# GD32F50x register map
File version: 1.0
CPU: CM33 r2p1, little endian, MPU, FPU, 4 interrupt priority bits
Registers are 32-bit, read-write, reset 0x0 unless marked. A register's access mark holds for its fields unless they carry their own. Offsets are from the block's base; [hi:lo] are bit positions; {n}, {i} and the like mark numbered series; 'fields as' and 'values as' point back to an identical list.

## DMAMUX — DMA request multiplexer
Base 0x40020800
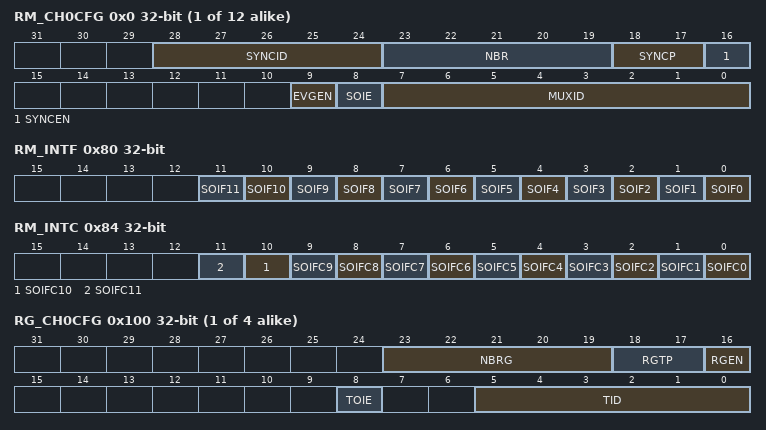
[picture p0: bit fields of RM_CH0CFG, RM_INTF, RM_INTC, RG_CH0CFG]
{0x0+4i} RM_CH{i}CFG (i=0..11) — Request multiplexer channel {i} configuration regist
  [28:24] SYNCID — Synchronization input identification
  [23:19] NBR — Number of DMA requests to forward
  [18:17] SYNCP — Synchronization input polarity
  [16] SYNCEN — Synchronization enable
  [9] EVGEN — Event generation enable
  [8] SOIE — Synchronization overrun interrupt enable
  [7:0] MUXID — Multiplexer input identification
0x80 RM_INTF ro — Request multiplexer channel interrupt flag register
  [n] SOIF{n} (n=0..11) — Synchronization overrun event flag of request multiplexer channel {n}
0x84 RM_INTC wo — Request multiplexer channel interrupt flag clear register
  [n] SOIFC{n} (n=0..11) — Clear bit for synchronization overrun event flag of request multiplexer channel {n}
{0x100+4i} RG_CH{i}CFG (i=0..3) — Request generator channel {i} configuration regist
  [23:19] NBRG — Number of DMA requests to be generated
  [18:17] RGTP — DMAMUX request generator trigger polarity
  [16] RGEN — DMAMUX request generator channel x enable
  [8] TOIE — Trigger overrun interrupt enable
  [5:0] TID — Trigger input identification
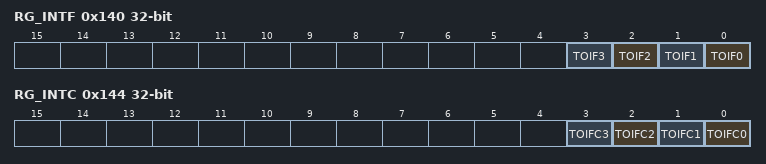
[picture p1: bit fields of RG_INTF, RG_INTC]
0x140 RG_INTF ro — Request generator channel interrupt flag register
  [n] TOIF{n} (n=0..3) — Trigger overrun event flag of request generator channel {n}
0x144 RG_INTC wo — Rquest generator channel interrupt flag clear register
  [n] TOIFC{n} (n=0..3) — Clear bit for trigger overrun event flag of request generator channel {n}

## TRIGSEL — Flash memory controller
Base 0x40014400
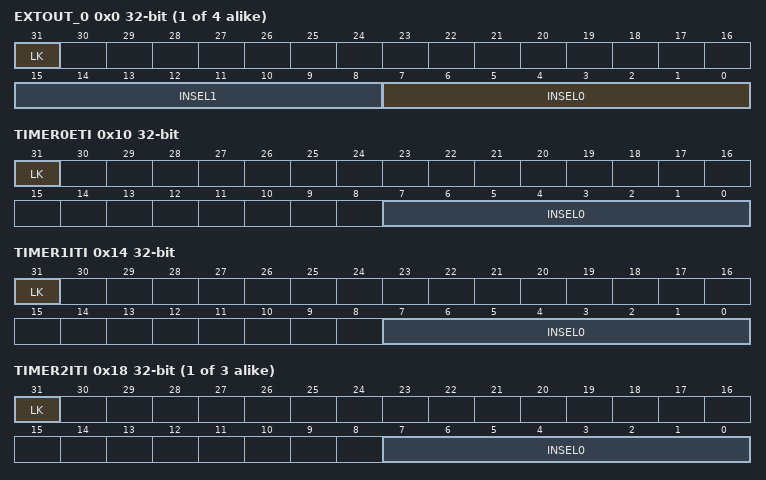
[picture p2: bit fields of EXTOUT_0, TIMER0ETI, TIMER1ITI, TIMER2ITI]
{0x0+4i} EXTOUT_{i} (i=0..3) — Trigger selection for EXTOUT register {i}
  [31] LK — TRIGSEL register lock.
  [15:8] INSEL1 — Trigger input source selection for output1
  [7:0] INSEL0 — Trigger input source selection for output0
0x10 TIMER0ETI — Trigger selection for TIMER0_ITI register
  [31] LK — TRIGSEL register lock.
  [7:0] INSEL0 — Trigger input source selection for output0
0x14 TIMER1ITI — Trigger selection for TIMER1_ETI register
  fields as TIMER0ETI
{0x10+4i} TIMER{i}ITI (i=2..4) — Trigger selection for TIMER{i}_ITI register
  fields as TIMER0ETI
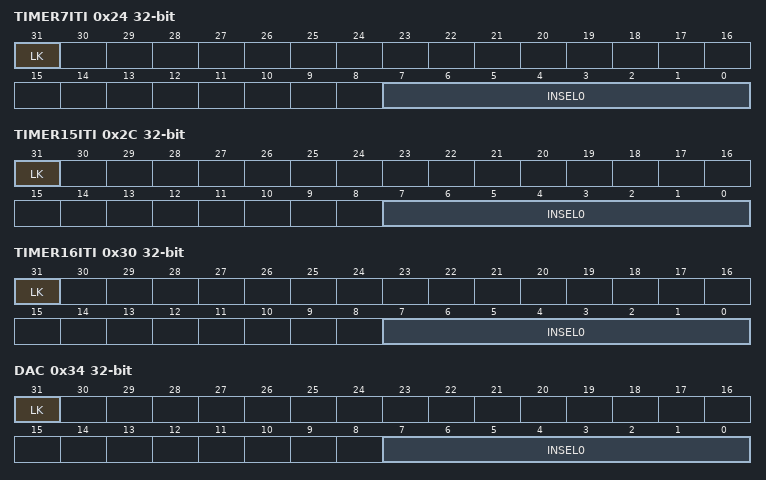
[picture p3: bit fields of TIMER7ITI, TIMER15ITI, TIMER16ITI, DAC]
0x24 TIMER7ITI — Trigger selection for TIMER7_ITI register
  fields as TIMER0ETI
0x2C TIMER15ITI — Trigger selection for TIMER15_ITI register
  fields as TIMER0ETI
0x30 TIMER16ITI — Trigger selection for TIMER16_ITI register
  fields as TIMER0ETI
0x34 DAC — Trigger selection for DAC register
  fields as TIMER0ETI
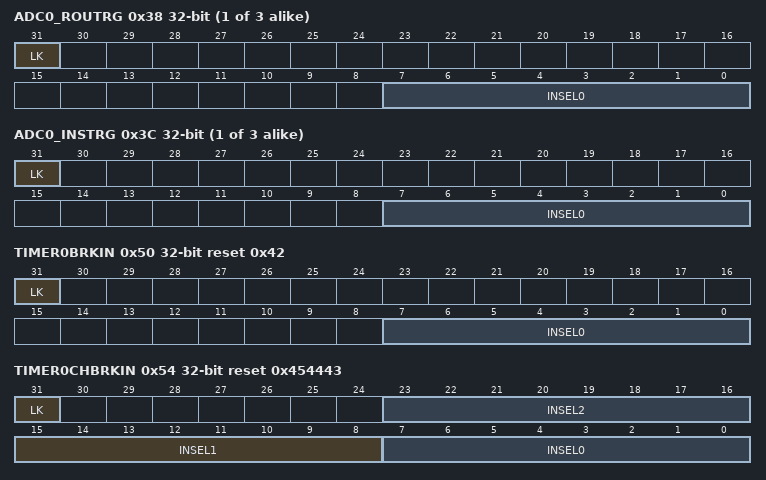
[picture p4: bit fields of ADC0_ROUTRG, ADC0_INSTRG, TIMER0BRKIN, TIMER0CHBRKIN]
{0x38+8i} ADC{i}_ROUTRG (i=0..2) — Trigger selection for ADC{i}_ROUTRG register
  fields as TIMER0ETI
{0x3C+8i} ADC{i}_INSTRG (i=0..2) — Trigger selection for ADC{i}_INSTRG register
  fields as TIMER0ETI
0x50 TIMER0BRKIN reset 0x42 — Trigger selection for TIMER0_BRKIN register
  [31] LK — TRIGSEL register lock.
  [7:0] INSEL0 — Trigger input source selection for TIMER0_BRKIN
0x54 TIMER0CHBRKIN reset 0x454443 — Trigger selection for TIMER0_CHBRKIN register
  [31] LK — TRIGSEL register lock.
  [23:16] INSEL2 — Trigger input source selection for TIMER0_CH2BRKIN.
  [15:8] INSEL1 — Trigger input source selection for TIMER0_CH1BRKIN
  [7:0] INSEL0 — Trigger input source selection for TIMER0_CH0BRKIN
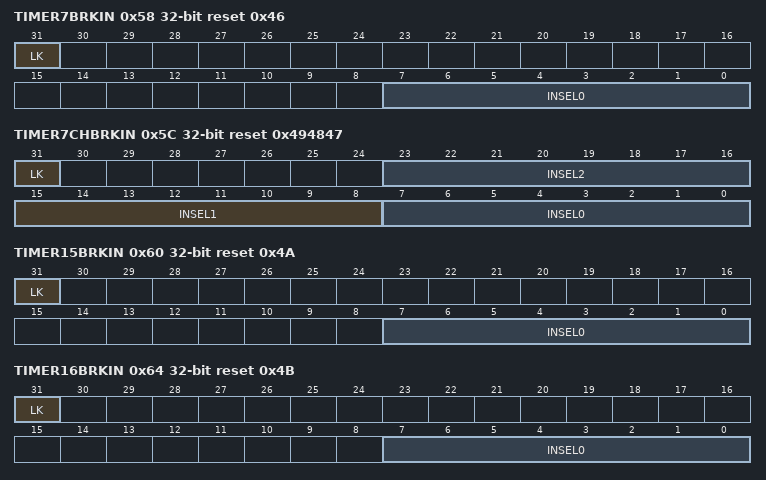
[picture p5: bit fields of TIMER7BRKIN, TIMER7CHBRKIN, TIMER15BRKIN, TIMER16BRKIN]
0x58 TIMER7BRKIN reset 0x46 — Trigger selection for TIMER7_BRKIN register
  [31] LK — TRIGSEL register lock.
  [7:0] INSEL0 — Trigger input source selection for TIMER7_BRKIN
0x5C TIMER7CHBRKIN reset 0x494847 — Trigger selection for TIMER7_CHBRKIN register
  [31] LK — TRIGSEL register lock.
  [23:16] INSEL2 — Trigger input source selection for TIMER7_CH2BRKIN.
  [15:8] INSEL1 — Trigger input source selection for TIMER7_CH1BRKIN
  [7:0] INSEL0 — Trigger input source selection for TIMER7_CH0BRKIN
0x60 TIMER15BRKIN reset 0x4A — Trigger selection for TIMER15_BRKIN register
  [31] LK — TRIGSEL register lock.
  [7:0] INSEL0 — Trigger input source selection for TIMER15_BRKIN.
0x64 TIMER16BRKIN reset 0x4B — Trigger selection for TIMER16_BRKIN register
  [31] LK — TRIGSEL register lock.
  [7:0] INSEL0 — Trigger input source selection for TIMER16_BRKIN
